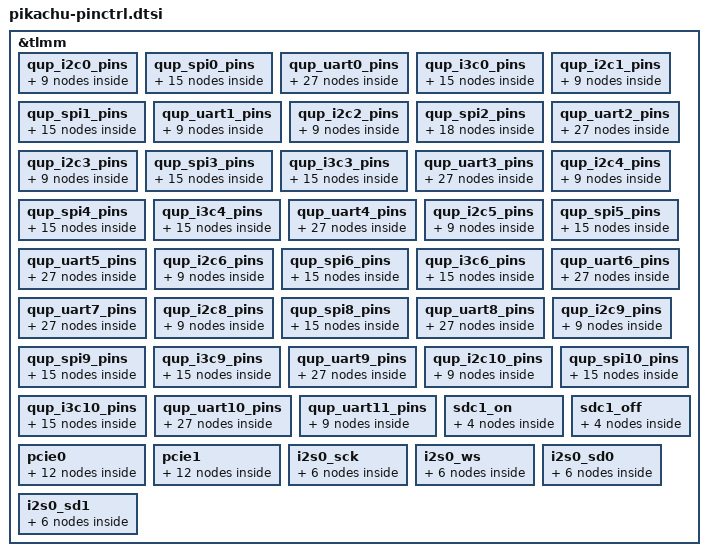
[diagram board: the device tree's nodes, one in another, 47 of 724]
// SPDX-License-Identifier: BSD-3-Clause
/*
 * Copyright (c) Qualcomm Technologies, Inc. and/or its subsidiaries.
 */

&tlmm {
	qup_i2c0_pins: qup_i2c0_pins {
		qup_i2c0_sda_active: qup_i2c0_sda_active {
			mux {
				pins = "gpio22";
				function = "qup0_se0_l0";
			};

			config {
				pins = "gpio22";
				drive-strength = <2>;
				bias-pull-up;
				qcom,i2c_pull;
			};
		};

		qup_i2c0_scl_active: qup_i2c0_scl_active {
			mux {
				pins = "gpio23";
				function = "qup0_se0_l1";
			};

			config {
				pins = "gpio23";
				drive-strength = <2>;
				bias-pull-up;
				qcom,i2c_pull;
			};
		};

		qup_i2c0_sleep: qup_i2c0_sleep {
			mux {
				pins = "gpio22", "gpio23";
				function = "gpio";
			};

			config {
				pins = "gpio22", "gpio23";
				drive-strength = <2>;
			};
		};
	};

	qup_spi0_pins: qup_spi0_pins {
		qup_spi0_miso_active: qup_spi0_miso_active {
			mux {
				pins = "gpio22";
				function = "qup0_se0_l0";
			};

			config {
				pins = "gpio22";
				drive-strength = <6>;
				bias-disable;
			};
		};

		qup_spi0_mosi_active: qup_spi0_mosi_active {
			mux {
				pins = "gpio23";
				function = "qup0_se0_l1";
			};

			config {
				pins = "gpio23";
				drive-strength = <6>;
				bias-disable;
			};
		};

		qup_spi0_clk_active: qup_spi0_clk_active {
			mux {
				pins = "gpio12";
				function = "qup0_se0_l2";
			};

			config {
				pins = "gpio12";
				drive-strength = <6>;
				bias-disable;
			};
		};

		qup_spi0_cs_active: qup_spi0_cs_active {
			mux {
				pins = "gpio13";
				function = "qup0_se0_l3";
			};

			config {
				pins = "gpio13";
				drive-strength = <6>;
				bias-disable;
			};
		};

		qup_spi0_sleep: qup_spi0_sleep {
			mux {
				pins = "gpio22", "gpio23",
					"gpio12", "gpio13";
				function = "gpio";
			};

			config {
				pins = "gpio22", "gpio23",
					"gpio12", "gpio13";
				drive-strength = <2>;
				bias-disable;
			};
		};
	};

	qup_uart0_pins: qup_uart0_pins {
		qup_uart0_default_cts: qup_uart0_default_cts {
			mux {
				pins = "gpio22";
				function = "gpio";
			};

			config {
				pins = "gpio22";
				drive-strength = <2>;
				bias-pull-down;
			};
		};

		qup_uart0_default_rts: qup_uart0_default_rts {
			mux {
				pins = "gpio23";
				function = "gpio";
			};

			config {
				pins = "gpio23";
				drive-strength = <2>;
				bias-pull-down;
			};
		};

		qup_uart0_default_tx: qup_uart0_default_tx {
			mux {
				pins = "gpio12";
				function = "gpio";
			};

			config {
				pins = "gpio12";
				drive-strength = <2>;
				bias-pull-up;
			};
		};

		qup_uart0_default_rx: qup_uart0_default_rx {
			mux {
				pins = "gpio13";
				function = "gpio";
			};

			config {
				pins = "gpio13";
				drive-strength = <2>;
				bias-pull-down;
			};
		};

		qup_uart0_cts: qup_uart0_cts {
			mux {
				pins = "gpio22";
				function = "qup0_se0_l0";
			};

			config {
				pins = "gpio22";
				drive-strength = <2>;
				bias-disable;
			};
		};

		qup_uart0_rts: qup_uart0_rts {
			mux {
				pins = "gpio23";
				function = "qup0_se0_l1";
			};

			config {
				pins = "gpio23";
				drive-strength = <2>;
				bias-pull-down;
			};
		};

		qup_uart0_tx: qup_uart0_tx {
			mux {
				pins = "gpio12";
				function = "qup0_se0_l2";
			};

			config {
				pins = "gpio12";
				drive-strength = <2>;
				bias-pull-up;
			};
		};

		qup_uart0_rx_active: qup_uart0_rx_active {
			mux {
				pins = "gpio13";
				function = "qup0_se0_l3";
			};

			config {
				pins = "gpio13";
				drive-strength = <2>;
				bias-disable;
			};
		};

		qup_uart0_rx_wake: qup_uart0_rx_wake {
			mux {
				pins = "gpio13";
				function = "gpio";
			};

			config {
				pins = "gpio13";
				drive-strength = <2>;
				bias-disable;
			};
		};
	};

	qup_i3c0_pins: qup_i3c0_pins {
		qup_i3c0_sda_active: qup_i3c0_sda_active {
			mux {
				pins = "gpio22";
				function = "ibi_i3c";
			};

			config {
				pins = "gpio22";
				drive-strength = <2>;
				bias-pull-up;
			};
		};

		qup_i3c0_scl_active: qup_i3c0_scl_active {
			mux {
				pins = "gpio23";
				function = "ibi_i3c";
			};

			config {
				pins = "gpio23";
				drive-strength = <2>;
				bias-pull-up;
			};
		};

		qup_i3c0_sda_sleep: qup_i3c0_sda_sleep {
			mux {
				pins = "gpio22";
				function = "ibi_i3c";
			};

			config {
				pins = "gpio22";
				drive-strength = <2>;
				bias-pull-up;
			};
		};

		qup_i3c0_scl_sleep: qup_i3c0_scl_sleep {
			mux {
				pins = "gpio23";
				function = "ibi_i3c";
			};

			config {
				pins = "gpio23";
				drive-strength = <2>;
				bias-pull-up;
			};
		};

		qup_i3c0_disable: qup_i3c0_disable {
			mux {
				pins = "gpio22", "gpio23";
				function = "gpio";
			};

			config {
				pins = "gpio22", "gpio23";
				drive-strength = <2>;
				bias-disable;
			};
		};
	};

	qup_i2c1_pins: qup_i2c1_pins {
		qup_i2c1_sda_active: qup_i2c1_sda_active {
			mux {
				pins = "gpio110";
				function = "qup0_se1_l0";
			};

			config {
				pins = "gpio110";
				drive-strength = <2>;
				bias-pull-up;
				qcom,i2c_pull;
			};
		};

		qup_i2c1_scl_active: qup_i2c1_scl_active {
			mux {
				pins = "gpio111";
				function = "qup0_se1_l1";
			};

			config {
				pins = "gpio111";
				drive-strength = <2>;
				bias-pull-up;
				qcom,i2c_pull;
			};
		};

		qup_i2c1_sleep: qup_i2c1_sleep {
			mux {
				pins = "gpio110", "gpio111";
				function = "gpio";
			};

			config {
				pins = "gpio110", "gpio111";
				drive-strength = <2>;
			};
		};
	};

	qup_spi1_pins: qup_spi1_pins {
		qup_spi1_miso_active: qup_spi1_miso_active {
			mux {
				pins = "gpio110";
				function = "qup0_se1_l0";
			};

			config {
				pins = "gpio110";
				drive-strength = <6>;
				bias-disable;
			};
		};

		qup_spi1_mosi_active: qup_spi1_mosi_active {
			mux {
				pins = "gpio111";
				function = "qup0_se1_l1";
			};

			config {
				pins = "gpio111";
				drive-strength = <6>;
				bias-disable;
			};
		};

		qup_spi1_clk_active: qup_spi1_clk_active {
			mux {
				pins = "gpio41";
				function = "qup0_se1_l2";
			};

			config {
				pins = "gpio41";
				drive-strength = <6>;
				bias-disable;
			};
		};

		qup_spi1_cs_active: qup_spi1_cs_active {
			mux {
				pins = "gpio42";
				function = "qup0_se1_l3";
			};

			config {
				pins = "gpio42";
				drive-strength = <6>;
				bias-disable;
			};
		};

		qup_spi1_sleep: qup_spi1_sleep {
			mux {
				pins = "gpio110", "gpio111",
					"gpio41", "gpio42";
				function = "gpio";
			};

			config {
				pins = "gpio110", "gpio111",
					"gpio41", "gpio42";
				drive-strength = <2>;
				bias-disable;
			};
		};
	};

	qup_uart1_pins: qup_uart1_pins {
		qup_uart1_tx_active: qup_uart1_tx_active {
			mux {
				pins = "gpio41";
				function = "qup0_se1_l2";
			};

			config {
				pins = "gpio41";
				drive-strength = <2>;
				bias-disable;
			};
		};

		qup_uart1_rx_active: qup_uart1_rx_active {
			mux {
				pins = "gpio42";
				function = "qup0_se1_l3";
			};

			config {
				pins = "gpio42";
				drive-strength = <2>;
				bias-disable;
			};
		};

		qup_uart1_sleep: qup_uart1_sleep {
			mux {
				pins = "gpio41", "gpio42";
				function = "gpio";
			};

			config {
				pins = "gpio41", "gpio42";
				drive-strength = <2>;
				bias-pull-down;
			};
		};
	};

	qup_i2c2_pins: qup_i2c2_pins {
		qup_i2c2_sda_active: qup_i2c2_sda_active {
			mux {
				pins = "gpio0";
				function = "qup0_se2_l0";
			};

			config {
				pins = "gpio0";
				drive-strength = <2>;
				bias-pull-up;
				qcom,i2c_pull;
			};
		};

		qup_i2c2_scl_active: qup_i2c2_scl_active {
			mux {
				pins = "gpio1";
				function = "qup0_se2_l1";
			};

			config {
				pins = "gpio1";
				drive-strength = <2>;
				bias-pull-up;
				qcom,i2c_pull;
			};
		};

		qup_i2c2_sleep: qup_i2c2_sleep {
			mux {
				pins = "gpio0", "gpio1";
				function = "gpio";
			};

			config {
				pins = "gpio0", "gpio1";
				drive-strength = <2>;
			};
		};
	};

	qup_spi2_pins: qup_spi2_pins {
		qup_spi2_miso_active: qup_spi2_miso_active {
			mux {
				pins = "gpio0";
				function = "qup0_se2_l0";
			};

			config {
				pins = "gpio0";
				drive-strength = <6>;
				bias-disable;
			};
		};

		qup_spi2_mosi_active: qup_spi2_mosi_active {
			mux {
				pins = "gpio1";
				function = "qup0_se2_l1";
			};

			config {
				pins = "gpio1";
				drive-strength = <6>;
				bias-disable;
			};
		};

		qup_spi2_clk_active: qup_spi2_clk_active {
			mux {
				pins = "gpio2";
				function = "qup0_se2_l2";
			};

			config {
				pins = "gpio2";
				drive-strength = <6>;
				bias-disable;
			};
		};

		qup_spi2_cs_active: qup_spi2_cs_active {
			mux {
				pins = "gpio3";
				function = "qup0_se2_l3";
			};

			config {
				pins = "gpio3";
				drive-strength = <6>;
				bias-disable;
			};
		};

		qup_spi2_sleep: qup_spi2_sleep {
			mux {
				pins = "gpio0", "gpio1",
					"gpio2", "gpio3";
				function = "gpio";
			};

			config {
				pins = "gpio0", "gpio1",
					"gpio2", "gpio3";
				drive-strength = <2>;
				bias-disable;
			};
		};

		qup_spi2_cs_gpio_sleep: qup_spi2_cs_gpio_sleep {
			mux {
				pins = "gpio0", "gpio1",
					"gpio2";
				function = "gpio";
			};

			config {
				pins = "gpio0", "gpio1",
					"gpio2";
				drive-strength = <2>;
				bias-disable;
			};
		};
	};

	qup_uart2_pins: qup_uart2_pins {
		qup_uart2_default_cts: qup_uart2_default_cts {
			mux {
				pins = "gpio0";
				function = "gpio";
			};

			config {
				pins = "gpio0";
				drive-strength = <2>;
				bias-pull-down;
			};
		};

		qup_uart2_default_rts: qup_uart2_default_rts {
			mux {
				pins = "gpio1";
				function = "gpio";
			};

			config {
				pins = "gpio1";
				drive-strength = <2>;
				bias-pull-down;
			};
		};

		qup_uart2_default_tx: qup_uart2_default_tx {
			mux {
				pins = "gpio2";
				function = "gpio";
			};

			config {
				pins = "gpio2";
				drive-strength = <2>;
				bias-pull-up;
			};
		};

		qup_uart2_default_rx: qup_uart2_default_rx {
			mux {
				pins = "gpio3";
				function = "gpio";
			};

			config {
				pins = "gpio3";
				drive-strength = <2>;
				bias-pull-down;
			};
		};

		qup_uart2_cts: qup_uart2_cts {
			mux {
				pins = "gpio0";
				function = "qup0_se2_l0";
			};

			config {
				pins = "gpio0";
				drive-strength = <2>;
				bias-disable;
			};
		};

		qup_uart2_rts: qup_uart2_rts {
			mux {
				pins = "gpio1";
				function = "qup0_se2_l1";
			};

			config {
				pins = "gpio1";
				drive-strength = <2>;
				bias-pull-down;
			};
		};

		qup_uart2_tx: qup_uart2_tx {
			mux {
				pins = "gpio2";
				function = "qup0_se2_l2";
			};

			config {
				pins = "gpio2";
				drive-strength = <2>;
				bias-pull-up;
			};
		};

		qup_uart2_rx_active: qup_uart2_rx_active {
			mux {
				pins = "gpio3";
				function = "qup0_se2_l3";
			};

			config {
				pins = "gpio3";
				drive-strength = <2>;
				bias-disable;
			};
		};

		qup_uart2_rx_wake: qup_uart2_rx_wake {
			mux {
				pins = "gpio3";
				function = "gpio";
			};

			config {
				pins = "gpio3";
				drive-strength = <2>;
				bias-disable;
			};
		};
	};

	qup_i2c3_pins: qup_i2c3_pins {
		qup_i2c3_sda_active: qup_i2c3_sda_active {
			mux {
				pins = "gpio16";
				function = "qup0_se3_l0";
			};

			config {
				pins = "gpio16";
				drive-strength = <2>;
				bias-pull-up;
				qcom,i2c_pull;
			};
		};

		qup_i2c3_scl_active: qup_i2c3_scl_active {
			mux {
				pins = "gpio17";
				function = "qup0_se3_l1";
			};

			config {
				pins = "gpio17";
				drive-strength = <2>;
				bias-pull-up;
				qcom,i2c_pull;
			};
		};

		qup_i2c3_sleep: qup_i2c3_sleep {
			mux {
				pins = "gpio16", "gpio17";
				function = "gpio";
			};

			config {
				pins = "gpio16", "gpio17";
				drive-strength = <2>;
			};
		};
	};

	qup_spi3_pins: qup_spi3_pins {
		qup_spi3_miso_active: qup_spi3_miso_active {
			mux {
				pins = "gpio16";
				function = "qup0_se3_l0";
			};

			config {
				pins = "gpio16";
				drive-strength = <6>;
				bias-disable;
			};
		};

		qup_spi3_mosi_active: qup_spi3_mosi_active {
			mux {
				pins = "gpio17";
				function = "qup0_se3_l1";
			};

			config {
				pins = "gpio17";
				drive-strength = <6>;
				bias-disable;
			};
		};

		qup_spi3_clk_active: qup_spi3_clk_active {
			mux {
				pins = "gpio18";
				function = "qup0_se3_l2";
			};

			config {
				pins = "gpio18";
				drive-strength = <6>;
				bias-disable;
			};
		};

		qup_spi3_cs_active: qup_spi3_cs_active {
			mux {
				pins = "gpio19";
				function = "qup0_se3_l3";
			};

			config {
				pins = "gpio19";
				drive-strength = <6>;
				bias-disable;
			};
		};

		qup_spi3_sleep: qup_spi3_sleep {
			mux {
				pins = "gpio16", "gpio17",
					"gpio18", "gpio19";
				function = "gpio";
			};

			config {
				pins = "gpio16", "gpio17",
					"gpio18", "gpio19";
				drive-strength = <2>;
				bias-disable;
			};
		};
	};

	qup_i3c3_pins: qup_i3c3_pins {
		qup_i3c3_sda_active: qup_i3c3_sda_active {
			mux {
				pins = "gpio16";
				function = "ibi_i3c";
			};

			config {
				pins = "gpio16";
				drive-strength = <2>;
				bias-pull-up;
			};
		};

		qup_i3c3_scl_active: qup_i3c3_scl_active {
			mux {
				pins = "gpio17";
				function = "ibi_i3c";
			};

			config {
				pins = "gpio17";
				drive-strength = <2>;
				bias-pull-up;
			};
		};

		qup_i3c3_sda_sleep: qup_i3c3_sda_sleep {
			mux {
				pins = "gpio16";
				function = "ibi_i3c";
			};

			config {
				pins = "gpio16";
				drive-strength = <2>;
				bias-pull-up;
			};
		};

		qup_i3c3_scl_sleep: qup_i3c3_scl_sleep {
			mux {
				pins = "gpio17";
				function = "ibi_i3c";
			};

			config {
				pins = "gpio17";
				drive-strength = <2>;
				bias-pull-up;
			};
		};

		qup_i3c3_disable: qup_i3c3_disable {
			mux {
				pins = "gpio16", "gpio17";
				function = "gpio";
			};

			config {
				pins = "gpio16", "gpio17";
				drive-strength = <2>;
				bias-disable;
			};
		};
	};

	qup_uart3_pins: qup_uart3_pins {
		qup_uart3_default_cts: qup_uart3_default_cts {
			mux {
				pins = "gpio16";
				function = "gpio";
			};

			config {
				pins = "gpio16";
				drive-strength = <2>;
				bias-pull-down;
			};
		};

		qup_uart3_default_rts: qup_uart3_default_rts {
			mux {
				pins = "gpio17";
				function = "gpio";
			};

			config {
				pins = "gpio17";
				drive-strength = <2>;
				bias-pull-down;
			};
		};

		qup_uart3_default_tx: qup_uart3_default_tx {
			mux {
				pins = "gpio18";
				function = "gpio";
			};

			config {
				pins = "gpio18";
				drive-strength = <2>;
				bias-pull-up;
			};
		};

		qup_uart3_default_rx: qup_uart3_default_rx {
			mux {
				pins = "gpio19";
				function = "gpio";
			};

			config {
				pins = "gpio19";
				drive-strength = <2>;
				bias-pull-down;
			};
		};

		qup_uart3_cts: qup_uart3_cts {
			mux {
				pins = "gpio16";
				function = "qup0_se3_l0";
			};

			config {
				pins = "gpio16";
				drive-strength = <2>;
				bias-disable;
			};
		};

		qup_uart3_rts: qup_uart3_rts {
			mux {
				pins = "gpio17";
				function = "qup0_se3_l1";
			};

			config {
				pins = "gpio17";
				drive-strength = <2>;
				bias-pull-down;
			};
		};

		qup_uart3_tx: qup_uart3_tx {
			mux {
				pins = "gpio18";
				function = "qup0_se3_l2";
			};

			config {
				pins = "gpio18";
				drive-strength = <2>;
				bias-pull-up;
			};
		};

		qup_uart3_rx_active: qup_uart3_rx_active {
			mux {
				pins = "gpio19";
				function = "qup0_se3_l3";
			};

			config {
				pins = "gpio19";
				drive-strength = <2>;
				bias-disable;
			};
		};

		qup_uart3_rx_wake: qup_uart3_rx_wake {
			mux {
				pins = "gpio19";
				function = "gpio";
			};

			config {
				pins = "gpio19";
				drive-strength = <2>;
				bias-disable;
			};
		};
	};

	qup_i2c4_pins: qup_i2c4_pins {
		qup_i2c4_sda_active: qup_i2c4_sda_active {
			mux {
				pins = "gpio20";
				function = "qup0_se4_l0";
			};

			config {
				pins = "gpio20";
				drive-strength = <2>;
				bias-pull-up;
				qcom,i2c_pull;
			};
		};

		qup_i2c4_scl_active: qup_i2c4_scl_active {
			mux {
				pins = "gpio21";
				function = "qup0_se4_l1";
			};

			config {
				pins = "gpio21";
				drive-strength = <2>;
				bias-pull-up;
				qcom,i2c_pull;
			};
		};

		qup_i2c4_sleep: qup_i2c4_sleep {
			mux {
				pins = "gpio20", "gpio21";
				function = "gpio";
			};

			config {
				pins = "gpio20", "gpio21";
				drive-strength = <2>;
			};
		};
	};

	qup_spi4_pins: qup_spi4_pins {
		qup_spi4_miso_active: qup_spi4_miso_active {
			mux {
				pins = "gpio20";
				function = "qup0_se4_l0";
			};

			config {
				pins = "gpio20";
				drive-strength = <6>;
				bias-disable;
			};
		};

		qup_spi4_mosi_active: qup_spi4_mosi_active {
			mux {
				pins = "gpio21";
				function = "qup0_se4_l1";
			};

			config {
				pins = "gpio21";
				drive-strength = <6>;
				bias-disable;
			};
		};

		qup_spi4_clk_active: qup_spi4_clk_active {
			mux {
				pins = "gpio22";
				function = "qup0_se4_l2";
			};

			config {
				pins = "gpio22";
				drive-strength = <6>;
				bias-disable;
			};
		};

		qup_spi4_cs_active: qup_spi4_cs_active {
			mux {
				pins = "gpio23";
				function = "qup0_se4_l3";
			};

			config {
				pins = "gpio23";
				drive-strength = <6>;
				bias-disable;
			};
		};

		qup_spi4_sleep: qup_spi4_sleep {
			mux {
				pins = "gpio20", "gpio21",
					"gpio22", "gpio23";
				function = "gpio";
			};

			config {
				pins = "gpio20", "gpio21",
					"gpio22", "gpio23";
				drive-strength = <2>;
				bias-disable;
			};
		};
	};

	qup_i3c4_pins: qup_i3c4_pins {
		qup_i3c4_sda_active: qup_i3c4_sda_active {
			mux {
				pins = "gpio20";
				function = "ibi_i3c";
			};

			config {
				pins = "gpio20";
				drive-strength = <2>;
				bias-pull-up;
			};
		};

		qup_i3c4_scl_active: qup_i3c4_scl_active {
			mux {
				pins = "gpio21";
				function = "ibi_i3c";
			};

			config {
				pins = "gpio21";
				drive-strength = <2>;
				bias-pull-up;
			};
		};

		qup_i3c4_sda_sleep: qup_i3c4_sda_sleep {
			mux {
				pins = "gpio20";
				function = "ibi_i3c";
			};

			config {
				pins = "gpio20";
				drive-strength = <2>;
				bias-pull-up;
			};
		};

		qup_i3c4_scl_sleep: qup_i3c4_scl_sleep {
			mux {
				pins = "gpio21";
				function = "ibi_i3c";
			};

			config {
				pins = "gpio21";
				drive-strength = <2>;
				bias-pull-up;
			};
		};

		qup_i3c4_disable: qup_i3c4_disable {
			mux {
				pins = "gpio20", "gpio21";
				function = "gpio";
			};

			config {
				pins = "gpio20", "gpio21";
				drive-strength = <2>;
				bias-disable;
			};
		};
	};

	qup_uart4_pins: qup_uart4_pins {
		qup_uart4_default_cts: qup_uart4_default_cts {
			mux {
				pins = "gpio20";
				function = "gpio";
			};

			config {
				pins = "gpio20";
				drive-strength = <2>;
				bias-pull-down;
			};
		};

		qup_uart4_default_rts: qup_uart4_default_rts {
			mux {
				pins = "gpio21";
				function = "gpio";
			};

			config {
				pins = "gpio21";
				drive-strength = <2>;
				bias-pull-down;
			};
		};

		qup_uart4_default_tx: qup_uart4_default_tx {
			mux {
				pins = "gpio22";
				function = "gpio";
			};

			config {
				pins = "gpio22";
				drive-strength = <2>;
				bias-pull-up;
			};
		};

		qup_uart4_default_rx: qup_uart4_default_rx {
			mux {
				pins = "gpio23";
				function = "gpio";
			};

			config {
				pins = "gpio23";
				drive-strength = <2>;
				bias-pull-down;
			};
		};

		qup_uart4_cts: qup_uart4_cts {
			mux {
				pins = "gpio20";
				function = "qup0_se4_l0";
			};

			config {
				pins = "gpio20";
				drive-strength = <2>;
				bias-disable;
			};
		};

		qup_uart4_rts: qup_uart4_rts {
			mux {
				pins = "gpio21";
				function = "qup0_se4_l1";
			};

			config {
				pins = "gpio21";
				drive-strength = <2>;
				bias-pull-down;
			};
		};

		qup_uart4_tx: qup_uart4_tx {
			mux {
				pins = "gpio22";
				function = "qup0_se4_l2";
			};

			config {
				pins = "gpio22";
				drive-strength = <2>;
				bias-pull-up;
			};
		};

		qup_uart4_rx_active: qup_uart4_rx_active {
			mux {
				pins = "gpio23";
				function = "qup0_se4_l3";
			};

			config {
				pins = "gpio23";
				drive-strength = <2>;
				bias-disable;
			};
		};

		qup_uart4_rx_wake: qup_uart4_rx_wake {
			mux {
				pins = "gpio23";
				function = "gpio";
			};

			config {
				pins = "gpio23";
				drive-strength = <2>;
				bias-disable;
			};
		};
	};

	qup_i2c5_pins: qup_i2c5_pins {
		qup_i2c5_sda_active: qup_i2c5_sda_active {
			mux {
				pins = "gpio67";
				function = "qup0_se5_l0";
			};

			config {
				pins = "gpio67";
				drive-strength = <2>;
				bias-pull-up;
				qcom,i2c_pull;
			};
		};

		qup_i2c5_scl_active: qup_i2c5_scl_active {
			mux {
				pins = "gpio68";
				function = "qup0_se5_l1";
			};

			config {
				pins = "gpio68";
				drive-strength = <2>;
				bias-pull-up;
				qcom,i2c_pull;
			};
		};

		qup_i2c5_sleep: qup_i2c5_sleep {
			mux {
				pins = "gpio67", "gpio68";
				function = "gpio";
			};

			config {
				pins = "gpio67", "gpio68";
				drive-strength = <2>;
			};
		};
	};

	qup_spi5_pins: qup_spi5_pins {
		qup_spi5_miso_active: qup_spi5_miso_active {
			mux {
				pins = "gpio67";
				function = "qup0_se5_l0";
			};

			config {
				pins = "gpio67";
				drive-strength = <6>;
				bias-disable;
			};
		};

		qup_spi5_mosi_active: qup_spi5_mosi_active {
			mux {
				pins = "gpio68";
				function = "qup0_se5_l1";
			};

			config {
				pins = "gpio68";
				drive-strength = <6>;
				bias-disable;
			};
		};

		qup_spi5_clk_active: qup_spi5_clk_active {
			mux {
				pins = "gpio115";
				function = "qup0_se5_l2";
			};

			config {
				pins = "gpio115";
				drive-strength = <6>;
				bias-disable;
			};
		};

		qup_spi5_cs_active: qup_spi5_cs_active {
			mux {
				pins = "gpio116";
				function = "qup0_se5_l3";
			};

			config {
				pins = "gpio116";
				drive-strength = <6>;
				bias-disable;
			};
		};

		qup_spi5_sleep: qup_spi5_sleep {
			mux {
				pins = "gpio67", "gpio68",
					"gpio115", "gpio116";
				function = "gpio";
			};

			config {
				pins = "gpio67", "gpio68",
					"gpio115", "gpio116";
				drive-strength = <2>;
				bias-disable;
			};
		};
	};

	qup_uart5_pins: qup_uart5_pins {
		qup_uart5_default_cts: qup_uart5_default_cts {
			mux {
				pins = "gpio67";
				function = "gpio";
			};

			config {
				pins = "gpio67";
				drive-strength = <2>;
				bias-pull-down;
			};
		};

		qup_uart5_default_rts: qup_uart5_default_rts {
			mux {
				pins = "gpio68";
				function = "gpio";
			};

			config {
				pins = "gpio68";
				drive-strength = <2>;
				bias-pull-down;
			};
		};

		qup_uart5_default_tx: qup_uart5_default_tx {
			mux {
				pins = "gpio115";
				function = "gpio";
			};

			config {
				pins = "gpio115";
				drive-strength = <2>;
				bias-pull-up;
			};
		};

		qup_uart5_default_rx: qup_uart5_default_rx {
			mux {
				pins = "gpio116";
				function = "gpio";
			};

			config {
				pins = "gpio116";
				drive-strength = <2>;
				bias-pull-down;
			};
		};

		qup_uart5_cts: qup_uart5_cts {
			mux {
				pins = "gpio67";
				function = "qup0_se5_l0";
			};

			config {
				pins = "gpio67";
				drive-strength = <2>;
				bias-disable;
			};
		};

		qup_uart5_rts: qup_uart5_rts {
			mux {
				pins = "gpio68";
				function = "qup0_se5_l1";
			};

			config {
				pins = "gpio68";
				drive-strength = <2>;
				bias-pull-down;
			};
		};

		qup_uart5_tx: qup_uart5_tx {
			mux {
				pins = "gpio115";
				function = "qup0_se5_l2";
			};

			config {
				pins = "gpio115";
				drive-strength = <2>;
				bias-pull-up;
			};
		};

		qup_uart5_rx_active: qup_uart5_rx_active {
			mux {
				pins = "gpio116";
				function = "qup0_se5_l3";
			};

			config {
				pins = "gpio116";
				drive-strength = <2>;
				bias-disable;
			};
		};

		qup_uart5_rx_wake: qup_uart5_rx_wake {
			mux {
				pins = "gpio116";
				function = "gpio";
			};

			config {
				pins = "gpio116";
				drive-strength = <2>;
				bias-disable;
			};
		};
	};

	qup_i2c6_pins: qup_i2c6_pins {
		qup_i2c6_sda_active: qup_i2c6_sda_active {
			mux {
				pins = "gpio61";
				function = "qup1_se0_l0";
			};

			config {
				pins = "gpio61";
				drive-strength = <2>;
				bias-pull-up;
				qcom,i2c_pull;
			};
		};

		qup_i2c6_scl_active: qup_i2c6_scl_active {
			mux {
				pins = "gpio62";
				function = "qup1_se0_l1";
			};

			config {
				pins = "gpio62";
				drive-strength = <2>;
				bias-pull-up;
				qcom,i2c_pull;
			};
		};

		qup_i2c6_sleep: qup_i2c6_sleep {
			mux {
				pins = "gpio61", "gpio62";
				function = "gpio";
			};

			config {
				pins = "gpio61", "gpio62";
				drive-strength = <2>;
			};
		};
	};

	qup_spi6_pins: qup_spi6_pins {
		qup_spi6_miso_active: qup_spi6_miso_active {
			mux {
				pins = "gpio61";
				function = "qup1_se0_l0";
			};

			config {
				pins = "gpio61";
				drive-strength = <6>;
				bias-disable;
			};
		};

		qup_spi6_mosi_active: qup_spi6_mosi_active {
			mux {
				pins = "gpio62";
				function = "qup1_se0_l1";
			};

			config {
				pins = "gpio62";
				drive-strength = <6>;
				bias-disable;
			};
		};

		qup_spi6_clk_active: qup_spi6_clk_active {
			mux {
				pins = "gpio55";
				function = "qup1_se0_l2";
			};

			config {
				pins = "gpio55";
				drive-strength = <6>;
				bias-disable;
			};
		};

		qup_spi6_cs_active: qup_spi6_cs_active {
			mux {
				pins = "gpio56";
				function = "qup1_se0_l3";
			};

			config {
				pins = "gpio56";
				drive-strength = <6>;
				bias-disable;
			};
		};

		qup_spi6_sleep: qup_spi6_sleep {
			mux {
				pins = "gpio61", "gpio62",
					"gpio55", "gpio56";
				function = "gpio";
			};

			config {
				pins = "gpio61", "gpio62",
					"gpio55", "gpio56";
				drive-strength = <2>;
				bias-disable;
			};
		};
	};

	qup_i3c6_pins: qup_i3c6_pins {
		qup_i3c6_sda_active: qup_i3c6_sda_active {
			mux {
				pins = "gpio61";
				function = "ibi_i3c";
			};

			config {
				pins = "gpio61";
				drive-strength = <2>;
				bias-pull-up;
			};
		};

		qup_i3c6_scl_active: qup_i3c6_scl_active {
			mux {
				pins = "gpio62";
				function = "ibi_i3c";
			};

			config {
				pins = "gpio62";
				drive-strength = <2>;
				bias-pull-up;
			};
		};

		qup_i3c6_sda_sleep: qup_i3c6_sda_sleep {
			mux {
				pins = "gpio61";
				function = "ibi_i3c";
			};

			config {
				pins = "gpio61";
				drive-strength = <2>;
				bias-pull-up;
			};
		};

		qup_i3c6_scl_sleep: qup_i3c6_scl_sleep {
			mux {
				pins = "gpio62";
				function = "ibi_i3c";
			};

			config {
				pins = "gpio62";
				drive-strength = <2>;
				bias-pull-up;
			};
		};

		qup_i3c6_disable: qup_i3c6_disable {
			mux {
				pins = "gpio61", "gpio62";
				function = "gpio";
			};

			config {
				pins = "gpio61", "gpio62";
				drive-strength = <2>;
				bias-disable;
			};
		};
	};

	qup_uart6_pins: qup_uart6_pins {
		qup_uart6_default_cts: qup_uart6_default_cts {
			mux {
				pins = "gpio61";
				function = "gpio";
			};

			config {
				pins = "gpio61";
				drive-strength = <2>;
				bias-pull-down;
			};
		};

		qup_uart6_default_rts: qup_uart6_default_rts {
			mux {
				pins = "gpio62";
				function = "gpio";
			};

			config {
				pins = "gpio62";
				drive-strength = <2>;
				bias-pull-down;
			};
		};

		qup_uart6_default_tx: qup_uart6_default_tx {
			mux {
				pins = "gpio55";
				function = "gpio";
			};

			config {
				pins = "gpio55";
				drive-strength = <2>;
				bias-pull-up;
			};
		};

		qup_uart6_default_rx: qup_uart6_default_rx {
			mux {
				pins = "gpio56";
				function = "gpio";
			};

			config {
				pins = "gpio56";
				drive-strength = <2>;
				bias-pull-down;
			};
		};

		qup_uart6_cts: qup_uart6_cts {
			mux {
				pins = "gpio61";
				function = "qup1_se0_l0";
			};

			config {
				pins = "gpio61";
				drive-strength = <2>;
				bias-disable;
			};
		};

		qup_uart6_rts: qup_uart6_rts {
			mux {
				pins = "gpio62";
				function = "qup1_se0_l1";
			};

			config {
				pins = "gpio62";
				drive-strength = <2>;
				bias-pull-down;
			};
		};

		qup_uart6_tx: qup_uart6_tx {
			mux {
				pins = "gpio55";
				function = "qup1_se0_l2";
			};

			config {
				pins = "gpio55";
				drive-strength = <2>;
				bias-pull-up;
			};
		};

		qup_uart6_rx_active: qup_uart6_rx_active {
			mux {
				pins = "gpio56";
				function = "qup1_se0_l3";
			};

			config {
				pins = "gpio56";
				drive-strength = <2>;
				bias-disable;
			};
		};

		qup_uart6_rx_wake: qup_uart6_rx_wake {
			mux {
				pins = "gpio56";
				function = "gpio";
			};

			config {
				pins = "gpio56";
				drive-strength = <2>;
				bias-disable;
			};
		};
	};

	qup_uart7_pins: qup_uart7_pins {
		qup_uart7_default_cts: qup_uart7_default_cts {
			mux {
				pins = "gpio24";
				function = "gpio";
			};

			config {
				pins = "gpio24";
				drive-strength = <2>;
				bias-disable;
			};
		};

		qup_uart7_default_rts: qup_uart7_default_rts {
			mux {
				pins = "gpio25";
				function = "gpio";
			};

			config {
				pins = "gpio25";
				drive-strength = <2>;
				bias-pull-down;
			};
		};

		qup_uart7_default_tx: qup_uart7_default_tx {
			mux {
				pins = "gpio26";
				function = "gpio";
			};

			config {
				pins = "gpio26";
				drive-strength = <2>;
				bias-pull-up;
			};
		};

		qup_uart7_default_rx: qup_uart7_default_rx {
			mux {
				pins = "gpio27";
				function = "gpio";
			};

			config {
				pins = "gpio27";
				drive-strength = <2>;
				bias-pull-down;
			};
		};

		qup_uart7_cts: qup_uart7_cts {
			mux {
				pins = "gpio24";
				function = "qup1_se1_l0";
			};

			config {
				pins = "gpio24";
				drive-strength = <2>;
				bias-disable;
			};
		};

		qup_uart7_rts: qup_uart7_rts {
			mux {
				pins = "gpio25";
				function = "qup1_se1_l1";
			};

			config {
				pins = "gpio25";
				drive-strength = <2>;
				bias-pull-down;
			};
		};

		qup_uart7_tx: qup_uart7_tx {
			mux {
				pins = "gpio26";
				function = "qup1_se1_l2";
			};

			config {
				pins = "gpio26";
				drive-strength = <2>;
				bias-pull-up;
			};
		};

		qup_uart7_rx_active: qup_uart7_rx_active {
			mux {
				pins = "gpio27";
				function = "qup1_se1_l3";
			};

			config {
				pins = "gpio27";
				drive-strength = <2>;
				bias-disable;
			};
		};

		qup_uart7_rx_wake: qup_uart7_rx_wake {
			mux {
				pins = "gpio27";
				function = "gpio";
			};

			config {
				pins = "gpio27";
				drive-strength = <2>;
				bias-disable;
			};
		};
	};

	qup_i2c8_pins: qup_i2c8_pins {
		qup_i2c8_sda_active: qup_i2c8_sda_active {
			mux {
				pins = "gpio8";
				function = "qup1_se2_l0";
			};

			config {
				pins = "gpio8";
				drive-strength = <2>;
				bias-pull-up;
				qcom,i2c_pull;
			};
		};

		qup_i2c8_scl_active: qup_i2c8_scl_active {
			mux {
				pins = "gpio9";
				function = "qup1_se2_l1";
			};

			config {
				pins = "gpio9";
				drive-strength = <2>;
				bias-pull-up;
				qcom,i2c_pull;
			};
		};

		qup_i2c8_sleep: qup_i2c8_sleep {
			mux {
				pins = "gpio8", "gpio9";
				function = "gpio";
			};

			config {
				pins = "gpio8", "gpio9";
				drive-strength = <2>;
			};
		};
	};

	qup_spi8_pins: qup_spi8_pins {
		qup_spi8_miso_active: qup_spi8_miso_active {
			mux {
				pins = "gpio8";
				function = "qup1_se2_l0";
			};

			config {
				pins = "gpio8";
				drive-strength = <6>;
				bias-disable;
			};
		};

		qup_spi8_mosi_active: qup_spi8_mosi_active {
			mux {
				pins = "gpio9";
				function = "qup1_se2_l1";
			};

			config {
				pins = "gpio9";
				drive-strength = <6>;
				bias-disable;
			};
		};

		qup_spi8_clk_active: qup_spi8_clk_active {
			mux {
				pins = "gpio112";
				function = "qup1_se2_l2";
			};

			config {
				pins = "gpio112";
				drive-strength = <6>;
				bias-disable;
			};
		};

		qup_spi8_cs_active: qup_spi8_cs_active {
			mux {
				pins = "gpio113";
				function = "qup1_se2_l3";
			};

			config {
				pins = "gpio113";
				drive-strength = <6>;
				bias-disable;
			};
		};

		qup_spi8_sleep: qup_spi8_sleep {
			mux {
				pins = "gpio8", "gpio9",
					"gpio112", "gpio113";
				function = "gpio";
			};

			config {
				pins = "gpio8", "gpio9",
					"gpio112", "gpio113";
				drive-strength = <2>;
				bias-disable;
			};
		};
	};

	qup_uart8_pins: qup_uart8_pins {
		qup_uart8_default_cts: qup_uart8_default_cts {
			mux {
				pins = "gpio8";
				function = "gpio";
			};

			config {
				pins = "gpio8";
				drive-strength = <2>;
				bias-pull-down;
			};
		};

		qup_uart8_default_rts: qup_uart8_default_rts {
			mux {
				pins = "gpio9";
				function = "gpio";
			};

			config {
				pins = "gpio9";
				drive-strength = <2>;
				bias-pull-down;
			};
		};

		qup_uart8_default_tx: qup_uart8_default_tx {
			mux {
				pins = "gpio112";
				function = "gpio";
			};

			config {
				pins = "gpio112";
				drive-strength = <2>;
				bias-pull-up;
			};
		};

		qup_uart8_default_rx: qup_uart8_default_rx {
			mux {
				pins = "gpio113";
				function = "gpio";
			};

			config {
				pins = "gpio113";
				drive-strength = <2>;
				bias-pull-down;
			};
		};

		qup_uart8_cts: qup_uart8_cts {
			mux {
				pins = "gpio8";
				function = "qup1_se2_l0";
			};

			config {
				pins = "gpio8";
				drive-strength = <2>;
				bias-disable;
			};
		};

		qup_uart8_rts: qup_uart8_rts {
			mux {
				pins = "gpio9";
				function = "qup1_se2_l1";
			};

			config {
				pins = "gpio9";
				drive-strength = <2>;
				bias-pull-down;
			};
		};

		qup_uart8_tx: qup_uart8_tx {
			mux {
				pins = "gpio112";
				function = "qup1_se2_l2";
			};

			config {
				pins = "gpio112";
				drive-strength = <2>;
				bias-pull-up;
			};
		};

		qup_uart8_rx_active: qup_uart8_rx_active {
			mux {
				pins = "gpio113";
				function = "qup1_se2_l3";
			};

			config {
				pins = "gpio113";
				drive-strength = <2>;
				bias-disable;
			};
		};

		qup_uart8_rx_wake: qup_uart8_rx_wake {
			mux {
				pins = "gpio113";
				function = "gpio";
			};

			config {
				pins = "gpio113";
				drive-strength = <2>;
				bias-disable;
			};
		};
	};

	qup_i2c9_pins: qup_i2c9_pins {
		qup_i2c9_sda_active: qup_i2c9_sda_active {
			mux {
				pins = "gpio59";
				function = "qup1_se3_l0";
			};

			config {
				pins = "gpio59";
				drive-strength = <2>;
				bias-pull-up;
				qcom,i2c_pull;
			};
		};

		qup_i2c9_scl_active: qup_i2c9_scl_active {
			mux {
				pins = "gpio60";
				function = "qup1_se3_l1";
			};

			config {
				pins = "gpio60";
				drive-strength = <2>;
				bias-pull-up;
				qcom,i2c_pull;
			};
		};

		qup_i2c9_sleep: qup_i2c9_sleep {
			mux {
				pins = "gpio59", "gpio60";
				function = "gpio";
			};

			config {
				pins = "gpio59", "gpio60";
				drive-strength = <2>;
			};
		};
	};

	qup_spi9_pins: qup_spi9_pins {
		qup_spi9_miso_active: qup_spi9_miso_active {
			mux {
				pins = "gpio59";
				function = "qup1_se3_l0";
			};

			config {
				pins = "gpio59";
				drive-strength = <6>;
				bias-disable;
			};
		};

		qup_spi9_mosi_active: qup_spi9_mosi_active {
			mux {
				pins = "gpio60";
				function = "qup1_se3_l1";
			};

			config {
				pins = "gpio60";
				drive-strength = <6>;
				bias-disable;
			};
		};

		qup_spi9_clk_active: qup_spi9_clk_active {
			mux {
				pins = "gpio28";
				function = "qup1_se3_l2";
			};

			config {
				pins = "gpio28";
				drive-strength = <6>;
				bias-disable;
			};
		};

		qup_spi9_cs_active: qup_spi9_cs_active {
			mux {
				pins = "gpio29";
				function = "qup1_se3_l3";
			};

			config {
				pins = "gpio29";
				drive-strength = <6>;
				bias-disable;
			};
		};

		qup_spi9_sleep: qup_spi9_sleep {
			mux {
				pins = "gpio59", "gpio60",
					"gpio28", "gpio29";
				function = "gpio";
			};

			config {
				pins = "gpio59", "gpio60",
					"gpio28", "gpio29";
				drive-strength = <2>;
				bias-disable;
			};
		};
	};

	qup_i3c9_pins: qup_i3c9_pins {
		qup_i3c9_sda_active: qup_i3c9_sda_active {
			mux {
				pins = "gpio59";
				function = "ibi_i3c";
			};

			config {
				pins = "gpio59";
				drive-strength = <2>;
				bias-pull-up;
			};
		};

		qup_i3c9_scl_active: qup_i3c9_scl_active {
			mux {
				pins = "gpio60";
				function = "ibi_i3c";
			};

			config {
				pins = "gpio60";
				drive-strength = <2>;
				bias-pull-up;
			};
		};

		qup_i3c9_sda_sleep: qup_i3c9_sda_sleep {
			mux {
				pins = "gpio59";
				function = "ibi_i3c";
			};

			config {
				pins = "gpio59";
				drive-strength = <2>;
				bias-pull-up;
			};
		};

		qup_i3c9_scl_sleep: qup_i3c9_scl_sleep {
			mux {
				pins = "gpio60";
				function = "ibi_i3c";
			};

			config {
				pins = "gpio60";
				drive-strength = <2>;
				bias-pull-up;
			};
		};

		qup_i3c9_disable: qup_i3c9_disable {
			mux {
				pins = "gpio59", "gpio60";
				function = "gpio";
			};

			config {
				pins = "gpio59", "gpio60";
				drive-strength = <2>;
				bias-disable;
			};
		};
	};

	qup_uart9_pins: qup_uart9_pins {
		qup_uart9_default_cts: qup_uart9_default_cts {
			mux {
				pins = "gpio59";
				function = "gpio";
			};

			config {
				pins = "gpio59";
				drive-strength = <2>;
				bias-pull-down;
			};
		};

		qup_uart9_default_rts: qup_uart9_default_rts {
			mux {
				pins = "gpio60";
				function = "gpio";
			};

			config {
				pins = "gpio60";
				drive-strength = <2>;
				bias-pull-down;
			};
		};

		qup_uart9_default_tx: qup_uart9_default_tx {
			mux {
				pins = "gpio28";
				function = "gpio";
			};

			config {
				pins = "gpio28";
				drive-strength = <2>;
				bias-pull-up;
			};
		};

		qup_uart9_default_rx: qup_uart9_default_rx {
			mux {
				pins = "gpio29";
				function = "gpio";
			};

			config {
				pins = "gpio29";
				drive-strength = <2>;
				bias-pull-down;
			};
		};

		qup_uart9_cts: qup_uart9_cts {
			mux {
				pins = "gpio59";
				function = "qup1_se3_l0";
			};

			config {
				pins = "gpio59";
				drive-strength = <2>;
				bias-disable;
			};
		};

		qup_uart9_rts: qup_uart9_rts {
			mux {
				pins = "gpio60";
				function = "qup1_se3_l1";
			};

			config {
				pins = "gpio60";
				drive-strength = <2>;
				bias-pull-down;
			};
		};

		qup_uart9_tx: qup_uart9_tx {
			mux {
				pins = "gpio28";
				function = "qup1_se3_l2";
			};

			config {
				pins = "gpio28";
				drive-strength = <2>;
				bias-pull-up;
			};
		};

		qup_uart9_rx_active: qup_uart9_rx_active {
			mux {
				pins = "gpio29";
				function = "qup1_se3_l3";
			};

			config {
				pins = "gpio29";
				drive-strength = <2>;
				bias-disable;
			};
		};

		qup_uart9_rx_wake: qup_uart9_rx_wake {
			mux {
				pins = "gpio29";
				function = "gpio";
			};

			config {
				pins = "gpio29";
				drive-strength = <2>;
				bias-disable;
			};
		};
	};

	qup_i2c10_pins: qup_i2c10_pins {
		qup_i2c10_sda_active: qup_i2c10_sda_active {
			mux {
				pins = "gpio4";
				function = "qup1_se4_l0";
			};

			config {
				pins = "gpio4";
				drive-strength = <2>;
				bias-pull-up;
				qcom,i2c_pull;
			};
		};

		qup_i2c10_scl_active: qup_i2c10_scl_active {
			mux {
				pins = "gpio5";
				function = "qup1_se4_l1";
			};

			config {
				pins = "gpio5";
				drive-strength = <2>;
				bias-pull-up;
				qcom,i2c_pull;
			};
		};

		qup_i2c10_sleep: qup_i2c10_sleep {
			mux {
				pins = "gpio4", "gpio5";
				function = "gpio";
			};

			config {
				pins = "gpio4", "gpio5";
				drive-strength = <2>;
			};
		};
	};

	qup_spi10_pins: qup_spi10_pins {
		qup_spi10_miso_active: qup_spi10_miso_active {
			mux {
				pins = "gpio4";
				function = "qup1_se4_l0";
			};

			config {
				pins = "gpio4";
				drive-strength = <6>;
				bias-disable;
			};
		};

		qup_spi10_mosi_active: qup_spi10_mosi_active {
			mux {
				pins = "gpio5";
				function = "qup1_se4_l1";
			};

			config {
				pins = "gpio5";
				drive-strength = <6>;
				bias-disable;
			};
		};

		qup_spi10_clk_active: qup_spi10_clk_active {
			mux {
				pins = "gpio6";
				function = "qup1_se4_l2";
			};

			config {
				pins = "gpio6";
				drive-strength = <6>;
				bias-disable;
			};
		};

		qup_spi10_cs_active: qup_spi10_cs_active {
			mux {
				pins = "gpio7";
				function = "qup1_se4_l3";
			};

			config {
				pins = "gpio7";
				drive-strength = <6>;
				bias-disable;
			};
		};

		qup_spi10_sleep: qup_spi10_sleep {
			mux {
				pins = "gpio4", "gpio5",
					"gpio6", "gpio7";
				function = "gpio";
			};

			config {
				pins = "gpio4", "gpio5",
					"gpio6", "gpio7";
				drive-strength = <2>;
				bias-disable;
			};
		};
	};

	qup_i3c10_pins: qup_i3c10_pins {
		qup_i3c10_sda_active: qup_i3c10_sda_active {
			mux {
				pins = "gpio4";
				function = "ibi_i3c";
			};

			config {
				pins = "gpio4";
				drive-strength = <2>;
				bias-pull-up;
			};
		};

		qup_i3c10_scl_active: qup_i3c10_scl_active {
			mux {
				pins = "gpio5";
				function = "ibi_i3c";
			};

			config {
				pins = "gpio5";
				drive-strength = <2>;
				bias-pull-up;
			};
		};

		qup_i3c10_sda_sleep: qup_i3c10_sda_sleep {
			mux {
				pins = "gpio4";
				function = "ibi_i3c";
			};

			config {
				pins = "gpio4";
				drive-strength = <2>;
				bias-pull-up;
			};
		};

		qup_i3c10_scl_sleep: qup_i3c10_scl_sleep {
			mux {
				pins = "gpio5";
				function = "ibi_i3c";
			};

			config {
				pins = "gpio5";
				drive-strength = <2>;
				bias-pull-up;
			};
		};

		qup_i3c10_disable: qup_i3c10_disable {
			mux {
				pins = "gpio4", "gpio5";
				function = "gpio";
			};

			config {
				pins = "gpio4", "gpio5";
				drive-strength = <2>;
				bias-disable;
			};
		};
	};

	qup_uart10_pins: qup_uart10_pins {
		qup_uart10_default_cts: qup_uart10_default_cts {
			mux {
				pins = "gpio4";
				function = "gpio";
			};

			config {
				pins = "gpio4";
				drive-strength = <2>;
				bias-pull-down;
			};
		};

		qup_uart10_default_rts: qup_uart10_default_rts {
			mux {
				pins = "gpio5";
				function = "gpio";
			};

			config {
				pins = "gpio5";
				drive-strength = <2>;
				bias-pull-down;
			};
		};

		qup_uart10_default_tx: qup_uart10_default_tx {
			mux {
				pins = "gpio6";
				function = "gpio";
			};

			config {
				pins = "gpio6";
				drive-strength = <2>;
				bias-pull-up;
			};
		};

		qup_uart10_default_rx: qup_uart10_default_rx {
			mux {
				pins = "gpio7";
				function = "gpio";
			};

			config {
				pins = "gpio7";
				drive-strength = <2>;
				bias-pull-down;
			};
		};

		qup_uart10_cts: qup_uart10_cts {
			mux {
				pins = "gpio4";
				function = "qup1_se4_l0";
			};

			config {
				pins = "gpio4";
				drive-strength = <2>;
				bias-disable;
			};
		};

		qup_uart10_rts: qup_uart10_rts {
			mux {
				pins = "gpio5";
				function = "qup1_se4_l1";
			};

			config {
				pins = "gpio5";
				drive-strength = <2>;
				bias-pull-down;
			};
		};

		qup_uart10_tx: qup_uart10_tx {
			mux {
				pins = "gpio6";
				function = "qup1_se4_l2";
			};

			config {
				pins = "gpio6";
				drive-strength = <2>;
				bias-pull-up;
			};
		};

		qup_uart10_rx_active: qup_uart10_rx_active {
			mux {
				pins = "gpio7";
				function = "qup1_se4_l3";
			};

			config {
				pins = "gpio7";
				drive-strength = <2>;
				bias-disable;
			};
		};

		qup_uart10_rx_wake: qup_uart10_rx_wake {
			mux {
				pins = "gpio7";
				function = "gpio";
			};

			config {
				pins = "gpio7";
				drive-strength = <2>;
				bias-disable;
			};
		};
	};

	qup_uart11_pins: qup_uart11_pins {
		qup_uart11_tx_active: qup_uart11_tx_active {
			mux {
				pins = "gpio14";
				function = "qup1_se5_l2";
			};

			config {
				pins = "gpio14";
				drive-strength = <2>;
				bias-disable;
			};
		};

		qup_uart11_rx_active: qup_uart11_rx_active {
			mux {
				pins = "gpio15";
				function = "qup1_se5_l3";
			};

			config {
				pins = "gpio15";
				drive-strength = <2>;
				bias-disable;
			};
		};

		qup_uart11_sleep: qup_uart11_sleep {
			mux {
				pins = "gpio14", "gpio15";
				function = "gpio";
			};

			config {
				pins = "gpio14", "gpio15";
				drive-strength = <2>;
				bias-pull-down;
			};
		};
	};

	sdc1_on: sdc1_on {
		clk {
			pins = "sdc1_clk";
			drive-strength = <8>;
			bias-disable;
		};

		cmd {
			pins = "sdc1_cmd";
			drive-strength = <8>;
			bias-pull-up;
		};

		data {
			pins = "sdc1_data";
			drive-strength = <8>;
			bias-pull-up;
		};

		rclk {
			pins = "sdc1_rclk";
			bias-pull-down;
		};
	};

	sdc1_off: sdc1_off {
		clk {
			pins = "sdc1_clk";
			drive-strength = <2>;
			bias-bus-hold;
		};

		cmd {
			pins = "sdc1_cmd";
			drive-strength = <2>;
			bias-bus-hold;
		};

		data {
			pins = "sdc1_data";
			drive-strength = <2>;
			bias-bus-hold;
		};

		rclk {
			pins = "sdc1_rclk";
			bias-bus-hold;
		};
	};

	pcie0 {
		pcie0_perst_default: pcie0_perst_default {
			mux {
				pins = "gpio37";
				function = "gpio";
			};

			config {
				pins = "gpio37";
				drive-strength = <2>;
				bias-pull-down;
			};
		};

		pcie0_clkreq_default: pcie0_clkreq_default {
			mux {
				pins = "gpio38";
				function = "pcie0_clk_req_n";
			};

			config {
				pins = "gpio38";
				drive-strength = <2>;
				bias-pull-up;
			};
		};

		pcie0_wake_default: pcie0_wake_default {
			mux {
				pins = "gpio39";
				function = "gpio";
			};

			config {
				pins = "gpio39";
				drive-strength = <2>;
				bias-pull-up;
			};
		};

		pcie0_clkreq_sleep: pcie0_clkreq_sleep {
			mux {
				pins = "gpio38";
				function = "gpio";
			};

			config {
				pins = "gpio38";
				drive-strength = <2>;
				bias-pull-up;
				input-enable;
			};
		};
	};

	pcie1 {
		pcie1_perst_default: pcie1_perst_default {
			mux {
				pins = "gpio7";
				function = "gpio";
			};

			config {
				pins = "gpio7";
				drive-strength = <2>;
				bias-pull-down;
			};
		};

		pcie1_clkreq_default: pcie1_clkreq_default {
			mux {
				pins = "gpio40";
				function = "pcie1_clk_req_n";
			};

			config {
				pins = "gpio40";
				drive-strength = <2>;
				bias-pull-up;
			};
		};

		pcie1_wake_default: pcie1_wake_default {
			mux {
				pins = "gpio6";
				function = "gpio";
			};

			config {
				pins = "gpio6";
				drive-strength = <2>;
				bias-pull-up;
			};
		};

		pcie1_clkreq_sleep: pcie1_clkreq_sleep {
			mux {
				pins = "gpio40";
				function = "gpio";
			};

			config {
				pins = "gpio40";
				drive-strength = <2>;
				bias-pull-up;
			};
		};
	};
	i2s0_sck {
		i2s0_sck_sleep: i2s0_sck_sleep {
			mux {
				pins = "gpio18";
				function = "gpio";
			};

			config {
				pins = "gpio18";
				drive-strength = <2>;   /* 2 mA */
				bias-pull-down;         /* PULL DOWN */
				input-enable;
			};
		};

		i2s0_sck_active: i2s0_sck_active {
			mux {
				pins = "gpio18";
				function = "i2s0_sck";
			};

			config {
				pins = "gpio18";
				drive-strength = <8>;   /* 8 mA */
				bias-disable;           /* NO PULL */
				output-high;
			};
		};
	};

	i2s0_ws {
		i2s0_ws_sleep: i2s0_ws_sleep {
			mux {
				pins = "gpio19";
				function = "gpio";
			};

			config {
				pins = "gpio19";
				drive-strength = <2>;   /* 2 mA */
				bias-pull-down;         /* PULL DOWN */
				input-enable;
			};
		};

		i2s0_ws_active: i2s0_ws_active {
			mux {
				pins = "gpio19";
				function = "i2s0_ws";
			};

			config {
				pins = "gpio19";
				drive-strength = <8>;   /* 8 mA */
				bias-disable;           /* NO PULL */
				output-high;
			};
		};
	};

	i2s0_sd0 {
		i2s0_sd0_sleep: i2s0_sd0_sleep {
			mux {
				pins = "gpio16";
				function = "gpio";
			};

			config {
				pins = "gpio16";
				drive-strength = <2>;   /* 2 mA */
				bias-pull-down;         /* PULL DOWN */
				input-enable;
			};
		};

		i2s0_sd0_active: i2s0_sd0_active {
			mux {
				pins = "gpio16";
				function = "i2s0_data0";
			};

			config {
				pins = "gpio16";
				drive-strength = <8>;   /* 8 mA */
				bias-disable;           /* NO PULL */
				output-high;
			};
		};
	};

	i2s0_sd1 {
		i2s0_sd1_sleep: i2s0_sd1_sleep {
			mux {
				pins = "gpio17";
				function = "gpio";
			};

			config {
				pins = "gpio17";
				drive-strength = <2>;   /* 2 mA */
				bias-pull-down;         /* PULL DOWN */
				input-enable;
			};
		};

		i2s0_sd1_active: i2s0_sd1_active {
			mux {
				pins = "gpio17";
				function = "i2s0_data1";
			};

			config {
				pins = "gpio17";
				drive-strength = <8>;   /* 8 mA */
				bias-disable;           /* NO PULL */
				output-high;
			};
		};
	};
};
